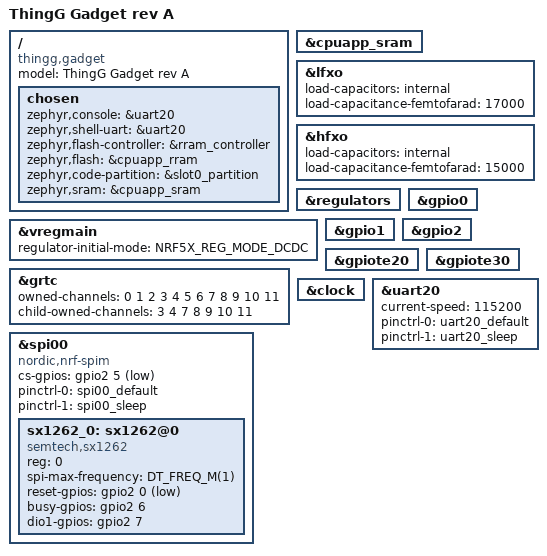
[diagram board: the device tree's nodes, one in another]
/*
 * Gadget rev A - custom board definition for the ThingG mesh communicator.
 *
 * MCU: nRF54L15 (Cortex-M33), dual SX1262 LoRa radios, e-ink, GPS.
 * This first revision only wires the debug console and LoRa radio #1;
 * the remaining peripherals land with their drivers in later milestones.
 */

/dts-v1/;

#include <nordic/nrf54l15_cpuapp.dtsi>
#include "gadget-pinctrl.dtsi"

/ {
	compatible = "thingg,gadget";
	model = "ThingG Gadget rev A";

	chosen {
		zephyr,console = &uart20;
		zephyr,shell-uart = &uart20;
		zephyr,flash-controller = &rram_controller;
		zephyr,flash = &cpuapp_rram;
		zephyr,code-partition = &slot0_partition;
		zephyr,sram = &cpuapp_sram;
	};
};

/* Include default memory partition configuration file */
#include <vendor/nordic/nrf54l15_cpuapp_partition.dtsi>

&cpuapp_sram {
	status = "okay";
};

&lfxo {
	load-capacitors = "internal";
	load-capacitance-femtofarad = <17000>;
};

&hfxo {
	load-capacitors = "internal";
	load-capacitance-femtofarad = <15000>;
};

&regulators {
	status = "okay";
};

&vregmain {
	status = "okay";
	regulator-initial-mode = <NRF5X_REG_MODE_DCDC>;
};

&grtc {
	owned-channels = <0 1 2 3 4 5 6 7 8 9 10 11>;
	/* Channels 7-11 reserved for Zero Latency IRQs, 3-4 for FLPR */
	child-owned-channels = <3 4 7 8 9 10 11>;
	status = "okay";
};

&gpio0 {
	status = "okay";
};

&gpio1 {
	status = "okay";
};

&gpio2 {
	status = "okay";
};

&gpiote20 {
	status = "okay";
};

&gpiote30 {
	status = "okay";
};

&clock {
	status = "okay";
};

&uart20 {
	status = "okay";
	current-speed = <115200>;
	pinctrl-0 = <&uart20_default>;
	pinctrl-1 = <&uart20_sleep>;
	pinctrl-names = "default", "sleep";
};

/* SX1262 #1, LoRa control plane, 915 MHz */
&spi00 {
	compatible = "nordic,nrf-spim";
	status = "okay";
	cs-gpios = <&gpio2 5 GPIO_ACTIVE_LOW>;
	pinctrl-0 = <&spi00_default>;
	pinctrl-1 = <&spi00_sleep>;
	pinctrl-names = "default", "sleep";

	sx1262_0: sx1262@0 {
		compatible = "semtech,sx1262";
		reg = <0>;
		spi-max-frequency = <DT_FREQ_M(1)>;
		reset-gpios = <&gpio2 0 GPIO_ACTIVE_LOW>;
		busy-gpios = <&gpio2 6 GPIO_ACTIVE_HIGH>;
		dio1-gpios = <&gpio2 7 GPIO_ACTIVE_HIGH>;
	};
};
